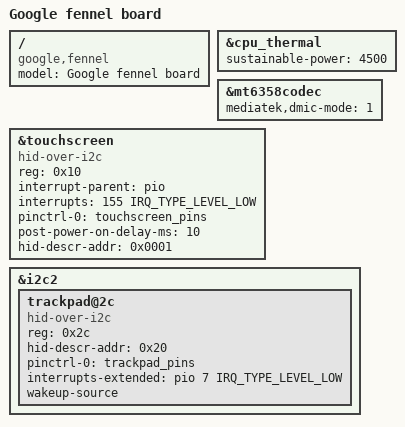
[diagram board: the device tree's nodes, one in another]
// SPDX-License-Identifier: (GPL-2.0 OR MIT)
/*
 * Copyright 2020 Google LLC
 */

/dts-v1/;
#include "mt8183-kukui-jacuzzi.dtsi"
#include "mt8183-kukui-audio-da7219.dtsi"

/ {
	model = "Google fennel board";
	compatible = "google,fennel", "mediatek,mt8183";
};

&cpu_thermal {
	sustainable-power = <4500>; /* milliwatts */
};

&mt6358codec {
	mediatek,dmic-mode = <1>; /* one-wire */
};

&touchscreen {
	status = "okay";

	compatible = "hid-over-i2c";
	reg = <0x10>;
	interrupt-parent = <&pio>;
	interrupts = <155 IRQ_TYPE_LEVEL_LOW>;
	pinctrl-names = "default";
	pinctrl-0 = <&touchscreen_pins>;

	post-power-on-delay-ms = <10>;
	hid-descr-addr = <0x0001>;
};

&i2c2 {
	trackpad@2c {
		compatible = "hid-over-i2c";
		reg = <0x2c>;
		hid-descr-addr = <0x20>;

		pinctrl-names = "default";
		pinctrl-0 = <&trackpad_pins>;

		interrupts-extended = <&pio 7 IRQ_TYPE_LEVEL_LOW>;

		wakeup-source;
	};
};
